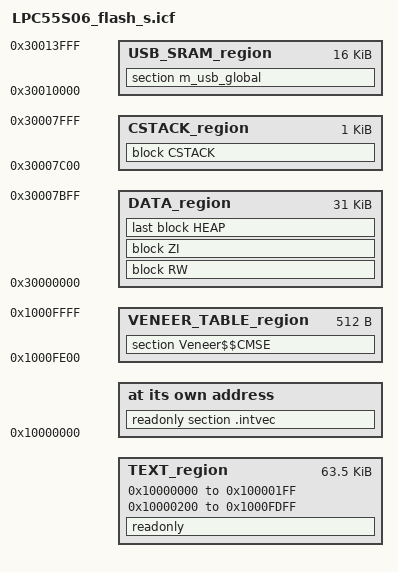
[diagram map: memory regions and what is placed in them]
/*
** ###################################################################
**     Processors:          LPC55S06JBD64
**                          LPC55S06JHI48
**
**     Compiler:            IAR ANSI C/C++ Compiler for ARM
**     Reference manual:    LPC55S1x/LPC551x User manual Rev.0.6  15 November 2019
**     Version:             rev. 1.0, 2020-04-09
**     Build:               b200415
**
**     Abstract:
**         Linker file for the IAR ANSI C/C++ Compiler for ARM
**
**     Copyright 2016 Freescale Semiconductor, Inc.
**     Copyright 2016-2020 NXP
**     All rights reserved.
**
**     SPDX-License-Identifier: BSD-3-Clause
**
**     http:                 www.nxp.com
**     mail:                 support@nxp.com
**
** ###################################################################
*/


/* USB BDT size */
define symbol usb_bdt_size             = 0x0;
/* Stack and Heap Sizes */
if (isdefinedsymbol(__stack_size__)) {
  define symbol __size_cstack__        = __stack_size__;
} else {
  define symbol __size_cstack__        = 0x0400;
}

if (isdefinedsymbol(__heap_size__)) {
  define symbol __size_heap__          = __heap_size__;
} else {
  define symbol __size_heap__          = 0x0400;
}

/* Only the first 64kB of flash is used as secure memory. */
define symbol m_interrupts_start               = 0x10000000;
define symbol m_interrupts_end                 = 0x100001FF;

define symbol m_text_start                     = 0x10000200;
define symbol m_text_end                       = 0x1000FDFF;

/* Only first 32kB of data RAM is used as secure memory. */
define symbol m_data_start                     = 0x30000000;
define symbol m_data_end                       = 0x30007FFF;

/* 512B - memory for veneer table (NSC - secure, non-secure callable memory) */
define symbol m_veneer_table_start             = 0x1000FE00;
define symbol m_veneer_table_size              = 0x200;

define symbol m_sramx_start                    = 0x14000000;
define symbol m_sramx_end                      = 0x14003FFF;

define symbol m_usb_sram_start                 = 0x30010000;
define symbol m_usb_sram_end                   = 0x30013FFF;

define memory mem with size = 4G;

define region TEXT_region             = mem:[from m_interrupts_start to m_interrupts_end]
                                      | mem:[from m_text_start to m_text_end];
define region DATA_region = mem:[from m_data_start to m_data_end-__size_cstack__];
define region CSTACK_region = mem:[from m_data_end-__size_cstack__+1 to m_data_end];
if (isdefinedsymbol(__use_shmem__)) {
  define region rpmsg_sh_mem_region     = mem:[from rpmsg_sh_mem_start to rpmsg_sh_mem_end];
}

define region VENEER_TABLE_region       = mem:[from m_veneer_table_start to m_veneer_table_start + m_veneer_table_size - 1];

define block CSTACK    with alignment = 8, size = __size_cstack__   { };
define block HEAP      with alignment = 8, size = __size_heap__     { };
define block RW        { readwrite };
define block ZI        { zi };


/* regions for USB */
define region USB_BDT_region = mem:[from m_usb_sram_start to m_usb_sram_start + usb_bdt_size - 1];
define region USB_SRAM_region = mem:[from m_usb_sram_start + usb_bdt_size to m_usb_sram_end];
place in USB_BDT_region                     { section m_usb_bdt };
place in USB_SRAM_region                    { section m_usb_global };

initialize by copy { readwrite, section .textrw };

if (isdefinedsymbol(__USE_DLIB_PERTHREAD))
{
  /* Required in a multi-threaded application */
  initialize by copy with packing = none { section __DLIB_PERTHREAD };
}

do not initialize  { section .noinit, section m_usb_bdt, section m_usb_global };
if (isdefinedsymbol(__use_shmem__)) {
  do not initialize  { section rpmsg_sh_mem_section };
}

place at address mem: m_interrupts_start    { readonly section .intvec };
place in TEXT_region                        { readonly };
place in DATA_region                        { block RW };
place in DATA_region                        { block ZI };
place in DATA_region                        { last block HEAP };
place in CSTACK_region                      { block CSTACK };
place in VENEER_TABLE_region                { section Veneer$$CMSE };



